# nrf9120_mlm1_modem register map
Vendor: Nordic Semiconductor; Series: nrf91; File version: 1
CPU: CM4 r0p1, little endian, MPU, no FPU, 3 interrupt priority bits
Registers are 32-bit, read-write, reset 0x0 unless marked. A register's access mark holds for its fields unless they carry their own. Offsets are from the block's base; [hi:lo] are bit positions; lines under a group give offsets from that group; 'fields as' and 'values as' point back to an identical list.

## UARTE — UART with EasyDMA
Base 0x40023000
0x00 TASKS_STARTRX wo — Start UART receiver
  [0] TASKS_STARTRX
    1=Trigger task
0x04 TASKS_STOPRX wo — Stop UART receiver
  [0] TASKS_STOPRX
    1=Trigger task
0x08 TASKS_STARTTX wo — Start UART transmitter
  [0] TASKS_STARTTX
    1=Trigger task
0x0C TASKS_STOPTX wo — Stop UART transmitter
  [0] TASKS_STOPTX
    1=Trigger task
0x1C TASKS_SUSPEND wo — Suspend UART transaction
  [0] TASKS_SUSPEND
    1=Trigger task
0x20 TASKS_RESUME wo — Resume UART transaction
  [0] TASKS_RESUME
    1=Trigger task
0x2C TASKS_FLUSHRX wo — Flush RX FIFO into RX buffer
  [0] TASKS_FLUSHRX
    1=Trigger task
0x100 EVENTS_CTS — CTS is activated (set low). Clear To Send.
  [0] EVENTS_CTS
    0=NotGenerated (Event not generated); 1=Generated (Event generated)
0x104 EVENTS_NCTS — CTS is deactivated (set high). Not Clear To Send.
  [0] EVENTS_NCTS
    values as EVENTS_CTS.EVENTS_CTS
0x108 EVENTS_RXDRDY — Data received in RXD (but potentially not yet transferred to Data RAM)
  [0] EVENTS_RXDRDY
    values as EVENTS_CTS.EVENTS_CTS
0x110 EVENTS_ENDRX — Receive buffer is filled up
  [0] EVENTS_ENDRX
    values as EVENTS_CTS.EVENTS_CTS
0x11C EVENTS_TXDRDY — Data sent from TXD
  [0] EVENTS_TXDRDY
    values as EVENTS_CTS.EVENTS_CTS
0x120 EVENTS_ENDTX — Last TX byte transmitted
  [0] EVENTS_ENDTX
    values as EVENTS_CTS.EVENTS_CTS
0x124 EVENTS_ERROR — Error detected
  [0] EVENTS_ERROR
    values as EVENTS_CTS.EVENTS_CTS
0x144 EVENTS_RXTO — Receiver timeout
  [0] EVENTS_RXTO
    values as EVENTS_CTS.EVENTS_CTS
0x14C EVENTS_RXSTARTED — UART receiver has started
  [0] EVENTS_RXSTARTED
    values as EVENTS_CTS.EVENTS_CTS
0x150 EVENTS_TXSTARTED — UART transmitter has started
  [0] EVENTS_TXSTARTED
    values as EVENTS_CTS.EVENTS_CTS
0x154 EVENTS_RTS — RX FIFO has only room for four more bytes before it overflows
  [0] EVENTS_RTS
    values as EVENTS_CTS.EVENTS_CTS
0x158 EVENTS_TXSTOPPED — Transmitter stopped
  [0] EVENTS_TXSTOPPED
    values as EVENTS_CTS.EVENTS_CTS
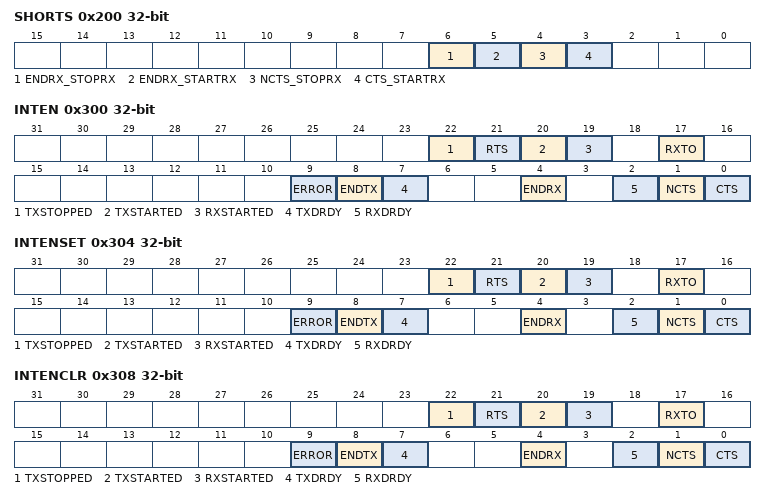
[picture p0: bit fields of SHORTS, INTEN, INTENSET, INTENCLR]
0x200 SHORTS — Shortcuts between local events and tasks
  [all] fields
    0=Disabled (Disable shortcut); 1=Enabled (Enable shortcut)
  [6] ENDRX_STOPRX — Shortcut between event ENDRX and task STOPRX
  [5] ENDRX_STARTRX — Shortcut between event ENDRX and task STARTRX
  [4] NCTS_STOPRX — Shortcut between event NCTS and task STOPRX
  [3] CTS_STARTRX — Shortcut between event CTS and task STARTRX
0x300 INTEN — Enable or disable interrupt
  [all] fields
    0=Disabled; 1=Enabled
  [22] TXSTOPPED — Enable or disable interrupt for event TXSTOPPED
  [21] RTS — Enable or disable interrupt for event RTS
  [20] TXSTARTED — Enable or disable interrupt for event TXSTARTED
  [19] RXSTARTED — Enable or disable interrupt for event RXSTARTED
  [17] RXTO — Enable or disable interrupt for event RXTO
  [9] ERROR — Enable or disable interrupt for event ERROR
  [8] ENDTX — Enable or disable interrupt for event ENDTX
  [7] TXDRDY — Enable or disable interrupt for event TXDRDY
  [4] ENDRX — Enable or disable interrupt for event ENDRX
  [2] RXDRDY — Enable or disable interrupt for event RXDRDY
  [1] NCTS — Enable or disable interrupt for event NCTS
  [0] CTS — Enable or disable interrupt for event CTS
0x304 INTENSET — Enable interrupt
  [all] fields
    on read: 0=Disabled (Read: Disabled); 1=Enabled (Read: Enabled) | on write: 1=Set (Enable)
  [22] TXSTOPPED — Write '1' to enable interrupt for event TXSTOPPED
  [21] RTS — Write '1' to enable interrupt for event RTS
  [20] TXSTARTED — Write '1' to enable interrupt for event TXSTARTED
  [19] RXSTARTED — Write '1' to enable interrupt for event RXSTARTED
  [17] RXTO — Write '1' to enable interrupt for event RXTO
  [9] ERROR — Write '1' to enable interrupt for event ERROR
  [8] ENDTX — Write '1' to enable interrupt for event ENDTX
  [7] TXDRDY — Write '1' to enable interrupt for event TXDRDY
  [4] ENDRX — Write '1' to enable interrupt for event ENDRX
  [2] RXDRDY — Write '1' to enable interrupt for event RXDRDY
  [1] NCTS — Write '1' to enable interrupt for event NCTS
  [0] CTS — Write '1' to enable interrupt for event CTS
0x308 INTENCLR — Disable interrupt
  [all] fields
    on read: 0=Disabled (Read: Disabled); 1=Enabled (Read: Enabled) | on write: 1=Clear (Disable)
  [22] TXSTOPPED — Write '1' to disable interrupt for event TXSTOPPED
  [21] RTS — Write '1' to disable interrupt for event RTS
  [20] TXSTARTED — Write '1' to disable interrupt for event TXSTARTED
  [19] RXSTARTED — Write '1' to disable interrupt for event RXSTARTED
  [17] RXTO — Write '1' to disable interrupt for event RXTO
  [9] ERROR — Write '1' to disable interrupt for event ERROR
  [8] ENDTX — Write '1' to disable interrupt for event ENDTX
  [7] TXDRDY — Write '1' to disable interrupt for event TXDRDY
  [4] ENDRX — Write '1' to disable interrupt for event ENDRX
  [2] RXDRDY — Write '1' to disable interrupt for event RXDRDY
  [1] NCTS — Write '1' to disable interrupt for event NCTS
  [0] CTS — Write '1' to disable interrupt for event CTS
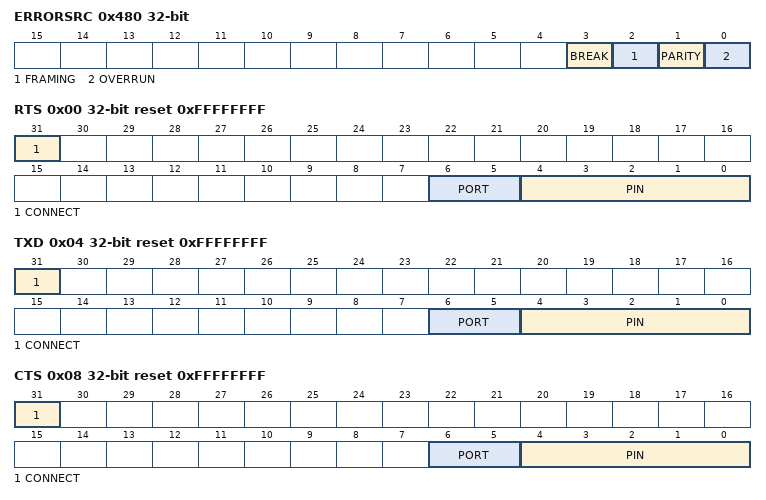
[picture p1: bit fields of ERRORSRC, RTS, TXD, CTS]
0x480 ERRORSRC write-1-clears — Error source
  [all] fields
    on read: 0=NotPresent (Read: error not present); 1=Present (Read: error present)
  [3] BREAK — Break condition
  [2] FRAMING — Framing error occurred
  [1] PARITY — Parity error
  [0] OVERRUN — Overrun error
0x500 ENABLE — Enable UART
  [3:0] ENABLE — Enable or disable UARTE
    0=Disabled (Disable UARTE); 8=Enabled (Enable UARTE)
0x508 PSEL group — Unspecified
  0x00 RTS reset 0xFFFFFFFF — Pin select for RTS signal
    [31] CONNECT — Connection
      1=Disconnected; 0=Connected
    [6:5] PORT — Port number
    [4:0] PIN — Pin number
  0x04 TXD reset 0xFFFFFFFF — Pin select for TXD signal
    fields as PSEL.RTS
  0x08 CTS reset 0xFFFFFFFF — Pin select for CTS signal
    fields as PSEL.RTS
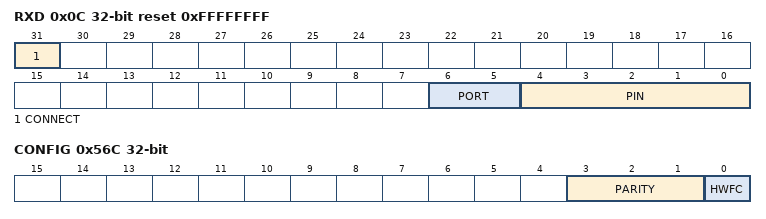
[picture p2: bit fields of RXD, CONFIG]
  0x0C RXD reset 0xFFFFFFFF — Pin select for RXD signal
    fields as PSEL.RTS
0x524 BAUDRATE reset 0x4000000
  [31:0] BAUDRATE
    0x3F000=Baud1200 (1200 baud (actual rate: 1202)); 0x7E000=Baud2400 (2400 baud (actual rate: 2403)); 0xFC000=Baud4800 (4800 baud (actual rate: 4807)); 0x1F7000=Baud9600 (9600 baud (actual rate: 9597)); 0x2F3000=Baud14400 (14400 baud (actual rate: 14409)); 0x3EE000=Baud19200 (19200 baud (actual rate: 19194)); 0x5E6000=Baud28800 (28800 baud (actual rate: 28818)); 0x7DC000=Baud38400 (38400 baud (actual rate: 38388)); 0xBC8000=Baud57600 (57600 baud (actual rate: 57637)); 0xFC0000=Baud76800 (76800 baud (actual rate: 76923)); 0x1780000=Baud115200 (115200 baud (actual rate: 114943)); 0x2F00000=Baud230400 (230400 baud (actual rate: 229885)); 0x3300000=Baud250000 (250000 baud); 0x5E00000=Baud460800 (460800 baud (actual rate: 465116)); 0xB800000=Baud921600 (921600 baud (actual rate: 909091)); 0xC800000=Baud1M (1Mega baud)
0x534 RXD group — RXD EasyDMA channel
  0x00 PTR — Data pointer
  0x04 MAXCNT — Maximum number of bytes in receive buffer
    [7:0] MAXCNT
  0x08 AMOUNT ro — Number of bytes transferred in the last transaction
    [7:0] AMOUNT
0x544 TXD group — TXD EasyDMA channel
  0x00 PTR — Data pointer
  0x04 MAXCNT — Maximum number of bytes in transmit buffer
    [7:0] MAXCNT
  0x08 AMOUNT ro — Number of bytes transferred in the last transaction
    [7:0] AMOUNT
0x56C CONFIG — Configuration of parity and hardware flow control
  [3:1] PARITY
    0=Excluded (Exclude parity bit); 7=Included (Include parity bit)
  [0] HWFC — Hardware flow control
    0=Disabled; 1=Enabled
0xFFC POWER reset 0x1 — Peripheral power control
  [0] POWER — Peripheral power control. The peripheral and its registers will be reset to its initial state by switching the peripheral off and then back on again.
    0=Disabled (Peripheral is powered off); 1=Enabled (Peripheral is powered on)
